# CC2753 register map
File version: 1.0
CPU: CM0+ r0p4, little endian, no MPU, no FPU, VTOR, 3 interrupt priority bits
Registers are 32-bit, read-write, reset 0x0 unless marked. A register's access mark holds for its fields unless they carry their own. Offsets are from the block's base; [hi:lo] are bit positions.

## SRAMCTRL — System SRAM Controller
Base 0x400C5000
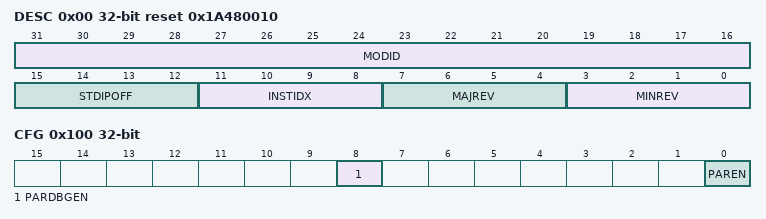
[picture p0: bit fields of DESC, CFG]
0x00 DESC ro reset 0x1A480010 — This register identifies the peripheral
  [31:16] MODID — Module identifier
  [15:12] STDIPOFF — 64 B Standard IP MMR block$lt;br$gt;0: STDIP MMRs do not exist$lt;br$gt;1:15: These MMRs begin at offset 64*STDIPOFF from IP base address
  [11:8] INSTIDX — IP Instance number
  [7:4] MAJREV — Major revision
  [3:0] MINREV — Minor revision
0x64 DTB — This bit field is used to select DTB mux digital inputs
  [1:0] SEL — DTB Selection
0x100 CFG — Configuration Register
  [8] PARDBGEN — SRAM Parity Debug Enable.
    1=EN (Enable Parity Debug. An address offset can be written to PARDBG.ADDR and parity errors will be generated on reads from within this offset); 0=DIS (Disable Parity Debug. Normal operation)
  [0] PAREN — SRAM Parity Enable.
    1=EN (Enable Parity); 0=DIS (Disable Parity)
0x104 INITSEL — Initilizataion Select Register.
  [2:0] SEL — Bank Select. Bit[0]:Bank-0 Bit[1]:Bank-1 ... Bit[n]:Bank-n
0x108 INITTRIG — Initilizataion Select Register. This register is writable only if CFG.LOCKDIS = 1
  [0] TRG — Trigger Initilization. All banks with its INIT.SEL[x] bit set to 1 will be initilizaed. This bit will auto clear once initlization is complete
0x10C INITSTAT ro — Initilizataion Status
  [2:0] BUSY — Each bit indicate that corresponding bank is getting initialzed
0x110 PARDBG — Parity error check debug address setting
  [19:2] ADDR — Debug Parity Error Address Offset.##br##When CFG.PARDBGEN is 1, this field is used to set a parity debug address offset. Writes within this address offset will force incorrect parity bits to be stored together with the data written. The following reads within this same address offset will thus result in parity errors to be generated.
0x114 PARERR ro — Parity error
  [31:0] ADDR — Parity Error Address Offset.##br##This holds the address offset that first generated the parity error and an interrupt is generated. ##br##This register is 'Clear-On-Read'

## SYSTICK
Base 0xE000E010
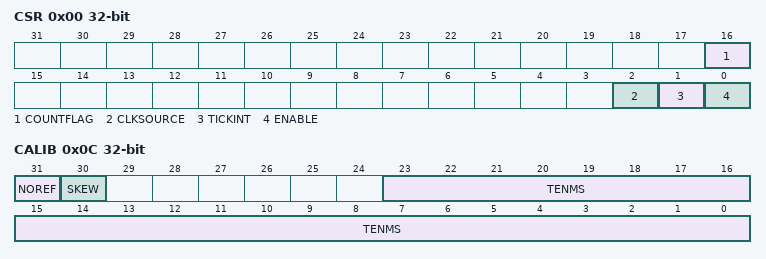
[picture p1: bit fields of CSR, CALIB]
0x00 CSR — SysTick Control and Status Register Use the SysTick Control and Status Register to enable the SysTick features.
  [16] COUNTFLAG ro — Returns 1 if timer counted to 0 since last time this was read. Clears on read by application or debugger.
  [2] CLKSOURCE ro — SysTick clock source. Always reads as one if STCALIB reports NOREF. 0x0:Systick driven by external reference clock. 0x1:Systick driven by processor clock
  [1] TICKINT — 0x0:Counting down to zero does not pend the systick handler. software can use countflag to determine if the systick handler has ever counted to zero. 0x1:Counting down to zero pends the systick handler.
  [0] ENABLE — Enable SysTick counter 0x0:Counter disabled 0x1:Counter operates in a multi-shot way. that is, counter loads with the reload value and then begins counting down. on reaching 0, it sets the countflag to 1 and optionally pends the systick handler, based on tickint. it then loads the reload value again, and begins counting.
0x04 RVR — SysTick Reload Value Register Use the SysTick Reload Value Register to specify the start value to load into the current value register when the counter reaches 0. It can be any value between 0 and 0x00FFFFFF. A start value of 0 is possible, but has no effect because the SysTick interrupt and COUNTFLAG are activated when counting from 1 to 0. The reset value of this register is UNKNOWN.
  [23:0] RELOAD — Value to load into the SysTick Current Value Register when the counter reaches 0.
0x08 CVR — SysTick Current Value Register Use the SysTick Current Value Register to find the current value in the register. The reset value of this register is UNKNOWN.
  [23:0] CURRENT — Reads return the current value of the SysTick counter. This register is write-clear. Writing to it with any value clears the register to 0. Clearing this register also clears the COUNTFLAG bit of the SysTick Control and Status Register.
0x0C CALIB — SysTick Calibration Value Register Use the SysTick Calibration Value Register to enable software to scale to any required speed using divide and multiply.
  [31] NOREF ro — If reads as 1, the Reference clock is not provided - the CLKSOURCE bit of the SysTick Control and Status register will be forced to 1 and cannot be cleared to 0.
  [30] SKEW ro — If reads as 1, the calibration value for 10ms is inexact (due to clock frequency).
  [23:0] TENMS ro — An optional Reload value to be used for 10ms (100Hz) timing, subject to system clock skew errors. If the value reads as 0, the calibration value is not known.
